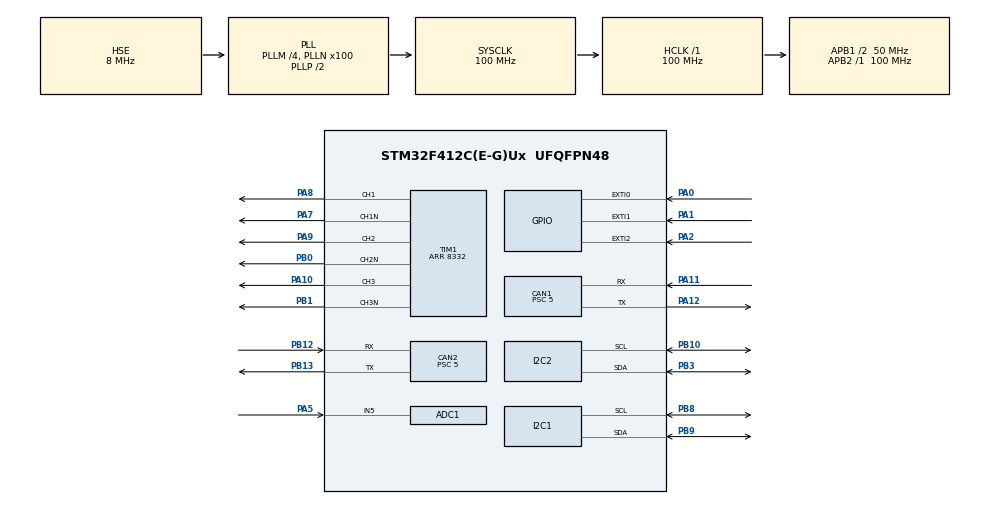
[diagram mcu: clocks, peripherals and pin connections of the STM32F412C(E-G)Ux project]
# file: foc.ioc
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ADC1.Channel-1\#ChannelRegularConversion=ADC_CHANNEL_5
ADC1.NbrOfConversionFlag=1
ADC1.Rank-1\#ChannelRegularConversion=1
ADC1.SamplingTime-1\#ChannelRegularConversion=ADC_SAMPLETIME_3CYCLES
ADC1.master=1
CAN1.BS1=CAN_BS1_14TQ
CAN1.BS2=CAN_BS2_5TQ
CAN1.CalculateBaudRate=500000
CAN1.CalculateTimeBit=2000
CAN1.CalculateTimeQuantum=100.0
CAN1.Prescaler=5
CAN1.SJW=CAN_SJW_1TQ
CAN2.BS1=CAN_BS1_14TQ
CAN2.BS2=CAN_BS2_5TQ
CAN2.CalculateBaudRate=500000
CAN2.CalculateTimeBit=2000
CAN2.CalculateTimeQuantum=100.0
CAN2.Prescaler=5
I2C1.I2C_Mode=I2C_Fast
I2C2.I2C_Mode=I2C_Fast
Mcu.Family=STM32F4
Mcu.Name=STM32F412C(E-G)Ux
Mcu.Package=UFQFPN48
NVIC.CAN1_RX0_IRQn=true\:2\:0\:true\:false\:true\:true\:true\:true
NVIC.CAN2_RX0_IRQn=true\:2\:0\:true\:false\:true\:true\:true\:true
NVIC.EXTI0_IRQn=true\:1\:0\:true\:false\:true\:true\:true\:true
NVIC.EXTI1_IRQn=true\:1\:0\:true\:false\:true\:true\:true\:true
NVIC.EXTI2_IRQn=true\:1\:0\:true\:false\:true\:true\:true\:true
NVIC.PriorityGroup=NVIC_PRIORITYGROUP_4
NVIC.TIM1_UP_TIM10_IRQn=true\:0\:0\:false\:false\:true\:true\:true\:true
PA0.GPIO_ModeDefaultEXTI=GPIO_MODE_IT_RISING_FALLING
PA0.GPIO_PuPd=GPIO_PULLUP
PA0.Signal=GPXTI0
PA1.GPIO_ModeDefaultEXTI=GPIO_MODE_IT_RISING_FALLING
PA1.GPIO_PuPd=GPIO_PULLUP
PA1.Signal=GPXTI1
PA10.Signal=S_TIM1_CH3
PA11.Mode=CAN_Activate
PA11.Signal=CAN1_RX
PA12.Mode=CAN_Activate
PA12.Signal=CAN1_TX
PA13.Mode=Serial_Wire
PA13.Signal=SYS_JTMS-SWDIO
PA14.Mode=Serial_Wire
PA14.Signal=SYS_JTCK-SWCLK
PA2.GPIO_ModeDefaultEXTI=GPIO_MODE_IT_RISING_FALLING
PA2.GPIO_PuPd=GPIO_PULLUP
PA2.Signal=GPXTI2
PA5.Signal=ADCx_IN5
PA7.Mode=PWM Generation1 CH1 CH1N
PA7.Signal=TIM1_CH1N
PA8.Signal=S_TIM1_CH1
PA9.Signal=S_TIM1_CH2
PB0.Mode=PWM Generation2 CH2 CH2N
PB0.Signal=TIM1_CH2N
PB1.Mode=PWM Generation3 CH3 CH3N
PB1.Signal=TIM1_CH3N
PB10.Mode=I2C
PB10.Signal=I2C2_SCL
PB12.Mode=CAN_Activate
PB12.Signal=CAN2_RX
PB13.Mode=CAN_Activate
PB13.Signal=CAN2_TX
PB3.Mode=I2C
PB3.Signal=I2C2_SDA
PB8.Mode=I2C
PB8.Signal=I2C1_SCL
PB9.Mode=I2C
PB9.Signal=I2C1_SDA
PH0\ -\ OSC_IN.Mode=HSE-External-Oscillator
PH0\ -\ OSC_IN.Signal=RCC_OSC_IN
PH1\ -\ OSC_OUT.Mode=HSE-External-Oscillator
PH1\ -\ OSC_OUT.Signal=RCC_OSC_OUT
ProjectManager.HeapSize=0x200
ProjectManager.StackSize=0x400
ProjectManager.TargetToolchain=MDK-ARM V5.32
RCC.AHBFreq_Value=100000000
RCC.APB1CLKDivider=RCC_HCLK_DIV2
RCC.APB1Freq_Value=50000000
RCC.APB1TimFreq_Value=100000000
RCC.APB2Freq_Value=100000000
RCC.APB2TimFreq_Value=100000000
RCC.CortexFreq_Value=100000000
RCC.HCLKFreq_Value=100000000
RCC.HSE_VALUE=8000000
RCC.PLLM=4
RCC.PLLN=100
RCC.PLLSourceVirtual=RCC_PLLSOURCE_HSE
RCC.SYSCLKFreq_VALUE=100000000
RCC.SYSCLKSource=RCC_SYSCLKSOURCE_PLLCLK
RCC.USBFreq_Value=100000000
RCC.VCOOutputFreq_Value=200000000
SH.ADCx_IN5.0=ADC1_IN5,IN5
SH.S_TIM1_CH1.0=TIM1_CH1,PWM Generation1 CH1 CH1N
SH.S_TIM1_CH2.0=TIM1_CH2,PWM Generation2 CH2 CH2N
SH.S_TIM1_CH3.0=TIM1_CH3,PWM Generation3 CH3 CH3N
TIM1.Channel-PWM\ Generation1\ CH1\ CH1N=TIM_CHANNEL_1
TIM1.Channel-PWM\ Generation2\ CH2\ CH2N=TIM_CHANNEL_2
TIM1.Channel-PWM\ Generation3\ CH3\ CH3N=TIM_CHANNEL_3
TIM1.DeadTime=50
TIM1.Period=8332
VP_TIM1_VS_ClockSourceINT.Mode=Internal
board=custom

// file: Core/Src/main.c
/* USER CODE BEGIN Header */
/**
  ******************************************************************************
  * @file           : main.c
  * @brief          : Main program body
  ******************************************************************************
  * @attention
  *
  * Copyright (c) 2026 STMicroelectronics.
  * All rights reserved.
  *
  * This software is licensed under terms that can be found in the LICENSE file
  * in the root directory of this software component.
  * If no LICENSE file comes with this software, it is provided AS-IS.
  *
  ******************************************************************************
  */
/* USER CODE END Header */
#include "main.h"
#include "adc.h"
#include "can.h"
#include "i2c.h"
#include "tim.h"
#include "gpio.h"

/* USER CODE BEGIN Includes */
#include "motor_app.h"
/* USER CODE END Includes */

void SystemClock_Config(void);

int main(void)
{

  /* MCU Configuration--------------------------------------------------------*/

  /* Reset of all peripherals, Initializes the Flash interface and the Systick. */
  HAL_Init();

  /* Configure the system clock */
  SystemClock_Config();

  /* Initialize all configured peripherals */
  MX_GPIO_Init();
  MX_TIM1_Init();
  MX_ADC1_Init();
  MX_CAN1_Init();
  MX_CAN2_Init();
  MX_I2C1_Init();
  MX_I2C2_Init();
  /* USER CODE BEGIN 2 */

	MotorApp_Init();

  /* USER CODE END 2 */

  /* Infinite loop */
  while (1)
  {

    /* USER CODE BEGIN 3 */
		 MotorApp_Loop();
  }
  /* USER CODE END 3 */
}

void SystemClock_Config(void)
{
  RCC_OscInitTypeDef RCC_OscInitStruct = {0};
  RCC_ClkInitTypeDef RCC_ClkInitStruct = {0};

  /** Configure the main internal regulator output voltage
  */
  __HAL_RCC_PWR_CLK_ENABLE();
  __HAL_PWR_VOLTAGESCALING_CONFIG(PWR_REGULATOR_VOLTAGE_SCALE1);

  /** Initializes the RCC Oscillators according to the specified parameters
  * in the RCC_OscInitTypeDef structure.
  */
  RCC_OscInitStruct.OscillatorType = RCC_OSCILLATORTYPE_HSE;
  RCC_OscInitStruct.HSEState = RCC_HSE_ON;
  RCC_OscInitStruct.PLL.PLLState = RCC_PLL_ON;
  RCC_OscInitStruct.PLL.PLLSource = RCC_PLLSOURCE_HSE;
  RCC_OscInitStruct.PLL.PLLM = 4;
  RCC_OscInitStruct.PLL.PLLN = 100;
  RCC_OscInitStruct.PLL.PLLP = RCC_PLLP_DIV2;
  RCC_OscInitStruct.PLL.PLLQ = 2;
  RCC_OscInitStruct.PLL.PLLR = 2;
  if (HAL_RCC_OscConfig(&RCC_OscInitStruct) != HAL_OK)
  {
    Error_Handler();
  }

  /** Initializes the CPU, AHB and APB buses clocks
  */
  RCC_ClkInitStruct.ClockType = RCC_CLOCKTYPE_HCLK|RCC_CLOCKTYPE_SYSCLK
                              |RCC_CLOCKTYPE_PCLK1|RCC_CLOCKTYPE_PCLK2;
  RCC_ClkInitStruct.SYSCLKSource = RCC_SYSCLKSOURCE_PLLCLK;
  RCC_ClkInitStruct.AHBCLKDivider = RCC_SYSCLK_DIV1;
  RCC_ClkInitStruct.APB1CLKDivider = RCC_HCLK_DIV2;
  RCC_ClkInitStruct.APB2CLKDivider = RCC_HCLK_DIV1;

  if (HAL_RCC_ClockConfig(&RCC_ClkInitStruct, FLASH_LATENCY_3) != HAL_OK)
  {
    Error_Handler();
  }
}

/* USER CODE BEGIN 4 */
/**
 * @brief  CAN����FIFO0�ص� (HAL��ص�)
 */
void HAL_CAN_RxFifo0MsgPendingCallback(CAN_HandleTypeDef *hcan)
{
    MotorApp_CAN_RxCallback(hcan);
}
/* USER CODE END 4 */

void Error_Handler(void)
{
  __disable_irq();
  while (1)
  {
  }
}
